AUTOSAR XML (schema 00044)
package /ComponentTypes
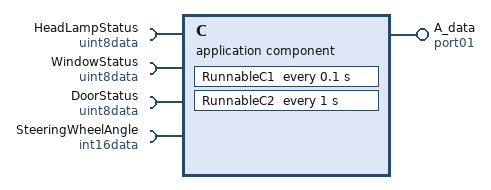
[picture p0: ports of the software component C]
  application sw component type C
    provide port A_data: provided-com-specs=[{data-element=Element1, init-value=0}, {data-element=Element2, init-value=0}], provided-interface=port01
    4 x require port:
      HeadLampStatus: nonqueued-receiver-com-spec{data-element=data, filter=data-filter-type=ALWAYS, init-value=0}, required-interface=uint8data
      WindowStatus: nonqueued-receiver-com-spec{data-element=data, filter=data-filter-type=ALWAYS, init-value=0}, required-interface=uint8data
      DoorStatus: nonqueued-receiver-com-spec{data-element=data, filter=data-filter-type=ALWAYS, init-value=0}, required-interface=uint8data
      SteeringWheelAngle: nonqueued-receiver-com-spec{data-element=Element, filter=data-filter-type=ALWAYS, init-value=0}, required-interface=int16data
    behavior C_InternalBehavior
      timing event TMT_RunnableC1: start-on-event=RunnableC1, period=0.1
      timing event TMT_RunnableC2: start-on-event=RunnableC2, period=1
      runnable RunnableC1
        data-receive-point-by-arguments:
          access REC_DoorStatus_data: accessed-variable=DoorStatus.data
          access REC_HeadLampStatus_data: accessed-variable=HeadLampStatus.data
        data-send-points:
          access SEND_port01_Element: accessed-variable=A_data.Element1
      runnable RunnableC2
        data-receive-point-by-arguments:
          access REC_SteeringWheelAngle_Element: accessed-variable=SteeringWheelAngle.Element
          access REC_WindowStatus_data: accessed-variable=WindowStatus.data
        data-send-points:
          access SEND_port01_Element_1: accessed-variable=A_data.Element2
  swc implementation C_Implementation: behavior=C_InternalBehavior
